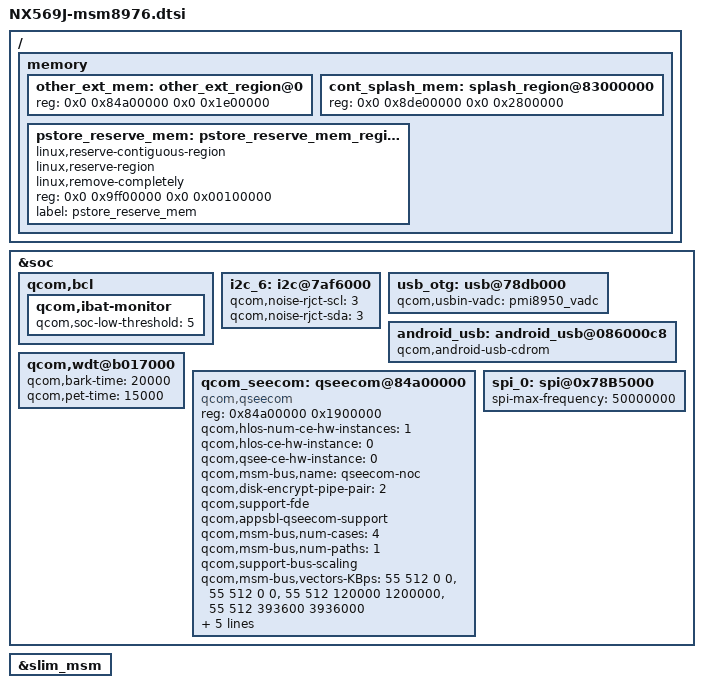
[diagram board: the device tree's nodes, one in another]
/*
 * Copyright (c) 2014-2016, The Linux Foundation. All rights reserved.
 *
 * This program is free software; you can redistribute it and/or modify
 * it under the terms of the GNU General Public License version 2 and
 * only version 2 as published by the Free Software Foundation.
 *
 * This program is distributed in the hope that it will be useful,
 * but WITHOUT ANY WARRANTY; without even the implied warranty of
 * MERCHANTABILITY or FITNESS FOR A PARTICULAR PURPOSE.  See the
 * GNU General Public License for more details.
 */

/ {
	memory {

		other_ext_mem: other_ext_region@0 {
			reg = <0x0 0x84a00000 0x0 0x1e00000>;
		};

		cont_splash_mem: splash_region@83000000 {
			reg = <0x0 0x8de00000 0x0 0x2800000>;
		};

		pstore_reserve_mem: pstore_reserve_mem_region@0 {
			linux,reserve-contiguous-region;
			linux,reserve-region;
			linux,remove-completely;
			reg = <0x0 0x9ff00000 0x0 0x00100000>;
			label = "pstore_reserve_mem";
		};
	};
};

&soc {

	qcom,bcl {
		qcom,ibat-monitor {
			qcom,soc-low-threshold = <5>;
		};
	};

	/delete-node/ uart@78af000;

	i2c_6: i2c@7af6000 { /* BLSP2 QUP2 */
		qcom,noise-rjct-scl = <3>;
		qcom,noise-rjct-sda = <3>;
	};

	usb_otg: usb@78db000 {
		//CONFIG_ZTEMT_COMMON_CHARGER add vbus detect
		qcom,usbin-vadc = <&pmi8950_vadc>;
	};

	android_usb: android_usb@086000c8 {
		qcom,android-usb-cdrom;
	};

	qcom,wdt@b017000 {
		qcom,bark-time = <20000>;
		qcom,pet-time = <15000>;
	};

	/delete-node/ qseecom@85b00000;
	qcom_seecom: qseecom@84a00000 {
		compatible = "qcom,qseecom";
		reg = <0x84a00000 0x1900000>;
		reg-names = "secapp-region";
		qcom,hlos-num-ce-hw-instances = <1>;
		qcom,hlos-ce-hw-instance = <0>;
		qcom,qsee-ce-hw-instance = <0>;
		qcom,msm-bus,name = "qseecom-noc";
		qcom,disk-encrypt-pipe-pair = <2>;
		qcom,support-fde;
		qcom,appsbl-qseecom-support;
		qcom,msm-bus,num-cases = <4>;
		qcom,msm-bus,num-paths = <1>;
		qcom,support-bus-scaling;
		qcom,msm-bus,vectors-KBps =
			<55 512 0 0>,
			<55 512 0 0>,
			<55 512 120000 1200000>,
			<55 512 393600 3936000>;
		clocks = <&clock_gcc clk_crypto_clk_src>,
			 <&clock_gcc clk_gcc_crypto_clk>,
			 <&clock_gcc clk_gcc_crypto_ahb_clk>,
			 <&clock_gcc clk_gcc_crypto_axi_clk>;
		clock-names = "core_clk_src", "core_clk",
				"iface_clk", "bus_clk";
		qcom,ce-opp-freq = <100000000>;
	};

	spi_0: spi@0x78B5000 { /* BLSP1 QUP0 */
		spi-max-frequency = <50000000>; //ZTEMT: changed from 19200000 to 50000000
		status = "ok";//ZTEMT:change by congshan 

	};

	/delete-node/ audio_ext_clk;
};

&slim_msm {
	/delete-node/ tasha_codec;
};

